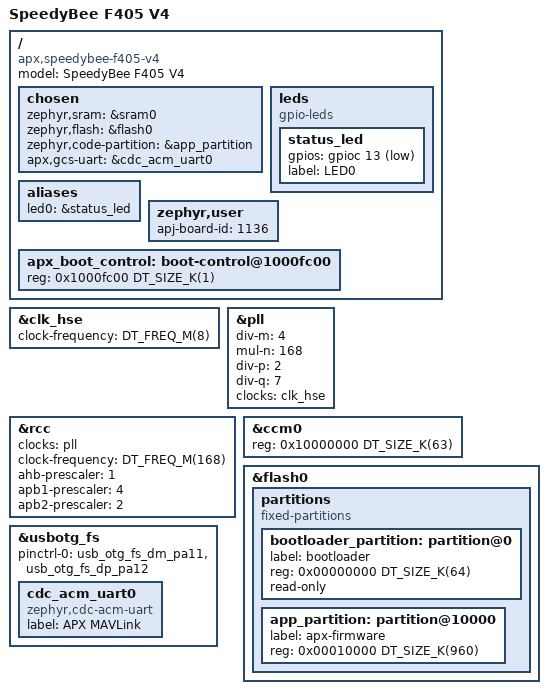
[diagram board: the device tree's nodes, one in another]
/*
 * SPDX-License-Identifier: CC-BY-NC-4.0
 * Copyright (c) 2026 Savita Pawar <savitapawar0402@gmail.com>
 * Author: Savita Pawar (SVPR94)
 * Created: 2026
 *
 * SpeedyBee F405 V4 (STM32F405xx).
 * Generated by tools/import_board.py from the board's hardware description; re-run it rather than editing.
 */
/dts-v1/;
#include <st/f4/stm32f405Xg.dtsi>
#include <st/f4/stm32f405rgtx-pinctrl.dtsi>
#include <zephyr/dt-bindings/gpio/gpio.h>

/ {
	model = "SpeedyBee F405 V4";
	compatible = "apx,speedybee-f405-v4";

	chosen {
		zephyr,sram = &sram0;
		zephyr,flash = &flash0;
		zephyr,code-partition = &app_partition;
		apx,gcs-uart = &cdc_acm_uart0;
	};

	leds {
		compatible = "gpio-leds";
		status_led: status_led {
			gpios = <&gpioc 13 GPIO_ACTIVE_LOW>;
			label = "LED0";
		};
	};

	aliases {
		led0 = &status_led;
	};

	/* APX board properties - see platforms/zephyr/app/src/board_zephyr.cpp */
	zephyr,user {
		apj-board-id = <1136>;
	};

	/* APX boot control (bootloader <-> firmware handshake), outside every
	 * image's RAM: the last 1 KB of ccm0. */
	apx_boot_control: boot-control@1000fc00 {
		reg = <0x1000fc00 DT_SIZE_K(1)>;
	};
};

&clk_hse {
	clock-frequency = <DT_FREQ_M(8)>;
	status = "okay";
};

/* 8 MHz / 4 * 168 = 336 MHz VCO; / 2 = 168 MHz SYSCLK, / 7 = 48 MHz USB */
&pll {
	div-m = <4>;
	mul-n = <168>;
	div-p = <2>;
	div-q = <7>;
	clocks = <&clk_hse>;
	status = "okay";
};

&rcc {
	clocks = <&pll>;
	clock-frequency = <DT_FREQ_M(168)>;
	ahb-prescaler = <1>;
	apb1-prescaler = <4>;
	apb2-prescaler = <2>;
};

&ccm0 {
	reg = <0x10000000 DT_SIZE_K(63)>;
};

&flash0 {
	partitions {
		compatible = "fixed-partitions";
		#address-cells = <1>;
		#size-cells = <1>;

		bootloader_partition: partition@0 {
			label = "bootloader";
			reg = <0x00000000 DT_SIZE_K(64)>;
			read-only;
		};
		app_partition: partition@10000 {
			label = "apx-firmware";
			reg = <0x00010000 DT_SIZE_K(960)>;
		};
	};
};

zephyr_udc0: &usbotg_fs {
	pinctrl-0 = <&usb_otg_fs_dm_pa11 &usb_otg_fs_dp_pa12>;
	pinctrl-names = "default";
	status = "okay";

	cdc_acm_uart0: cdc_acm_uart0 {
		compatible = "zephyr,cdc-acm-uart";
		label = "APX MAVLink";
	};
};
